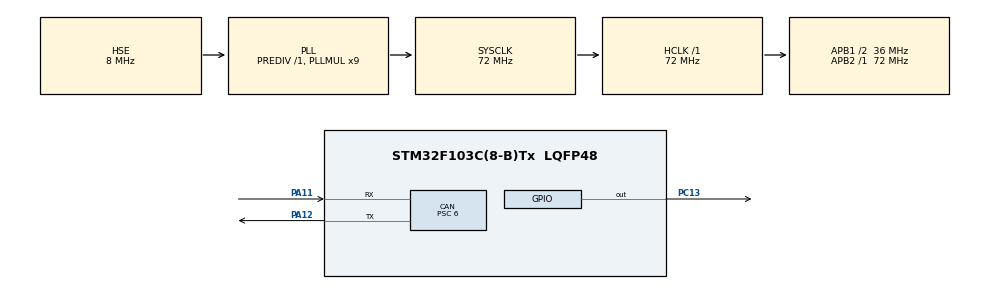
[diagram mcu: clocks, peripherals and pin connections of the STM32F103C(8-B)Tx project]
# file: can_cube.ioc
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CAN.BS1=CAN_BS1_3TQ
CAN.BS2=CAN_BS2_2TQ
CAN.CalculateTimeBit=1000
CAN.CalculateTimeQuantum=166.66666666666669
CAN.Mode=CAN_MODE_SILENT_LOOPBACK
CAN.Prescaler=6
Mcu.Family=STM32F1
Mcu.Name=STM32F103C(8-B)Tx
Mcu.Package=LQFP48
NVIC.PriorityGroup=NVIC_PRIORITYGROUP_4
NVIC.USB_LP_CAN1_RX0_IRQn=true\:0\:0\:false\:false\:true\:true\:true
PA11.Mode=Master
PA11.Signal=CAN_RX
PA12.Mode=Master
PA12.Signal=CAN_TX
PA13.Mode=Serial_Wire
PA13.Signal=SYS_JTMS-SWDIO
PA14.Mode=Serial_Wire
PA14.Signal=SYS_JTCK-SWCLK
PC13-TAMPER-RTC.GPIO_Speed=GPIO_SPEED_FREQ_HIGH
PC13-TAMPER-RTC.Signal=GPIO_Output
PD0-OSC_IN.Mode=HSE-External-Clock-Source
PD0-OSC_IN.Signal=RCC_OSC_IN
PD1-OSC_OUT.Mode=HSE-External-Clock-Source
PD1-OSC_OUT.Signal=RCC_OSC_OUT
ProjectManager.HeapSize=0x200
ProjectManager.StackSize=0x400
ProjectManager.TargetToolchain=MDK-ARM V5
RCC.AHBFreq_Value=72000000
RCC.APB1CLKDivider=RCC_HCLK_DIV2
RCC.APB1Freq_Value=36000000
RCC.APB1TimFreq_Value=72000000
RCC.APB2Freq_Value=72000000
RCC.APB2TimFreq_Value=72000000
RCC.HCLKFreq_Value=72000000
RCC.PLLMUL=RCC_PLL_MUL9
RCC.PLLSourceVirtual=RCC_PLLSOURCE_HSE
RCC.SYSCLKFreq_VALUE=72000000
RCC.SYSCLKSource=RCC_SYSCLKSOURCE_PLLCLK
RCC.USBFreq_Value=72000000
board=custom

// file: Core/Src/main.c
/* USER CODE BEGIN Header */
/**
  ******************************************************************************
  * @file           : main.c
  * @brief          : Main program body
  ******************************************************************************
  * @attention
  *
  * <h2><center>&copy; Copyright (c) 2020 STMicroelectronics.
  * All rights reserved.</center></h2>
  *
  * This software component is licensed by ST under BSD 3-Clause license,
  * the "License"; You may not use this file except in compliance with the
  * License. You may obtain a copy of the License at:
  *                        opensource.org/licenses/BSD-3-Clause
  *
  ******************************************************************************
  */
/* USER CODE END Header */
#include "main.h"
#include "can.h"
#include "gpio.h"

/* USER CODE BEGIN PM */
CAN_TxHeaderTypeDef CAN1_TX;
CAN_RxHeaderTypeDef CAN1_RX;
/* USER CODE END PM */

void SystemClock_Config(void);

/* USER CODE BEGIN 0 */

HAL_StatusTypeDef CAN1_Send_Msg(uint32_t StdId,uint8_t *msg)
{
//	RMLIB_ENTER_CRITICAL();
	CAN1_TX.StdId = StdId;								//标准标识符
	CAN1_TX.IDE = CAN_ID_STD;							//使用标准标识符
	CAN1_TX.RTR = CAN_RTR_DATA;						//数据帧
	CAN1_TX.DLC = 8;											//数据长度为8帧
	CAN1_TX.TransmitGlobalTime = DISABLE;	//捕获时间戳功能不启用

	HAL_StatusTypeDef err = HAL_CAN_AddTxMessage(&hcan,&CAN1_TX,msg,(uint32_t *)CAN_TX_MAILBOX0);

//	RMLIB_EXIT_CRITCAL();

	return err;
}
/* USER CODE END 0 */

int main(void)
{

  /* MCU Configuration--------------------------------------------------------*/

  /* Reset of all peripherals, Initializes the Flash interface and the Systick. */
  HAL_Init();

  /* Configure the system clock */
  SystemClock_Config();

  /* Initialize all configured peripherals */
  MX_GPIO_Init();
  MX_CAN_Init();
  /* USER CODE BEGIN 2 */

	/*配置CAN相关串口和中断*/
	HAL_CAN_MspInit(&hcan);

	/*配置滤波器*/
	CanFilter_Init(&hcan);

	/*启用can*/
	HAL_CAN_Start(&hcan);

	/*启用*/
	HAL_CAN_ActivateNotification(&hcan,CAN_IT_RX_FIFO0_MSG_PENDING);
  /* USER CODE END 2 */
  /* Infinite loop */
  while (1)
  {

  }
}

void SystemClock_Config(void)
{
  RCC_OscInitTypeDef RCC_OscInitStruct = {0};
  RCC_ClkInitTypeDef RCC_ClkInitStruct = {0};

  /** Initializes the RCC Oscillators according to the specified parameters
  * in the RCC_OscInitTypeDef structure.
  */
  RCC_OscInitStruct.OscillatorType = RCC_OSCILLATORTYPE_HSE;
  RCC_OscInitStruct.HSEState = RCC_HSE_BYPASS;
  RCC_OscInitStruct.HSEPredivValue = RCC_HSE_PREDIV_DIV1;
  RCC_OscInitStruct.HSIState = RCC_HSI_ON;
  RCC_OscInitStruct.PLL.PLLState = RCC_PLL_ON;
  RCC_OscInitStruct.PLL.PLLSource = RCC_PLLSOURCE_HSE;
  RCC_OscInitStruct.PLL.PLLMUL = RCC_PLL_MUL9;
  if (HAL_RCC_OscConfig(&RCC_OscInitStruct) != HAL_OK)
  {
    Error_Handler();
  }
  /** Initializes the CPU, AHB and APB buses clocks
  */
  RCC_ClkInitStruct.ClockType = RCC_CLOCKTYPE_HCLK|RCC_CLOCKTYPE_SYSCLK
                              |RCC_CLOCKTYPE_PCLK1|RCC_CLOCKTYPE_PCLK2;
  RCC_ClkInitStruct.SYSCLKSource = RCC_SYSCLKSOURCE_PLLCLK;
  RCC_ClkInitStruct.AHBCLKDivider = RCC_SYSCLK_DIV1;
  RCC_ClkInitStruct.APB1CLKDivider = RCC_HCLK_DIV2;
  RCC_ClkInitStruct.APB2CLKDivider = RCC_HCLK_DIV1;

  if (HAL_RCC_ClockConfig(&RCC_ClkInitStruct, FLASH_LATENCY_2) != HAL_OK)
  {
    Error_Handler();
  }
}

void Error_Handler(void)
{
}

/************************ (C) COPYRIGHT STMicroelectronics *****END OF FILE****/
